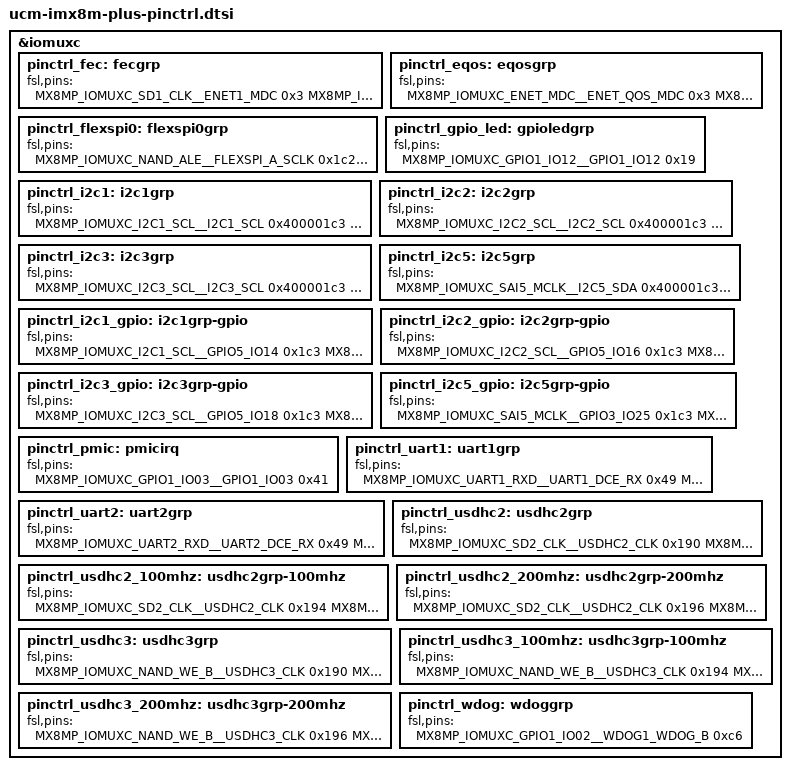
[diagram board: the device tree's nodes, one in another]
// SPDX-License-Identifier: (GPL-2.0+ OR MIT)
/*
 * Copyright 2022 CompuLab
 */

&iomuxc {
	pinctrl_fec: fecgrp {
		fsl,pins = <
			MX8MP_IOMUXC_SD1_CLK__ENET1_MDC					0x3
			MX8MP_IOMUXC_SD1_CMD__ENET1_MDIO				0x3
			MX8MP_IOMUXC_SD1_DATA2__ENET1_RGMII_RD0				0x91
			MX8MP_IOMUXC_SD1_DATA3__ENET1_RGMII_RD1				0x91
			MX8MP_IOMUXC_SAI1_RXD6__ENET1_RGMII_RD2				0x91
			MX8MP_IOMUXC_SAI1_RXD7__ENET1_RGMII_RD3				0x91
			MX8MP_IOMUXC_SAI1_TXC__ENET1_RGMII_RXC				0x91
			MX8MP_IOMUXC_SAI1_TXFS__ENET1_RGMII_RX_CTL			0x91
			MX8MP_IOMUXC_SD1_DATA1__ENET1_RGMII_TD0				0x1f
			MX8MP_IOMUXC_SD1_DATA0__ENET1_RGMII_TD1				0x1f
			MX8MP_IOMUXC_SAI1_TXD2__ENET1_RGMII_TD2				0x1f
			MX8MP_IOMUXC_SAI1_TXD3__ENET1_RGMII_TD3				0x1f
			MX8MP_IOMUXC_SAI1_TXD4__ENET1_RGMII_TX_CTL			0x1f
			MX8MP_IOMUXC_SAI1_TXD5__ENET1_RGMII_TXC				0x1f
		>;
	};
    
	pinctrl_eqos: eqosgrp {
		fsl,pins = <
			MX8MP_IOMUXC_ENET_MDC__ENET_QOS_MDC				0x3
			MX8MP_IOMUXC_ENET_MDIO__ENET_QOS_MDIO				0x3
			MX8MP_IOMUXC_ENET_RD0__ENET_QOS_RGMII_RD0			0x91
			MX8MP_IOMUXC_ENET_RD1__ENET_QOS_RGMII_RD1			0x91
			MX8MP_IOMUXC_ENET_RD2__ENET_QOS_RGMII_RD2			0x91
			MX8MP_IOMUXC_ENET_RD3__ENET_QOS_RGMII_RD3			0x91
			MX8MP_IOMUXC_ENET_RXC__CCM_ENET_QOS_CLOCK_GENERATE_RX_CLK	0x91
			MX8MP_IOMUXC_ENET_RX_CTL__ENET_QOS_RGMII_RX_CTL			0x91
			MX8MP_IOMUXC_ENET_TD0__ENET_QOS_RGMII_TD0			0x1f
			MX8MP_IOMUXC_ENET_TD1__ENET_QOS_RGMII_TD1			0x1f
			MX8MP_IOMUXC_ENET_TD2__ENET_QOS_RGMII_TD2			0x1f
			MX8MP_IOMUXC_ENET_TD3__ENET_QOS_RGMII_TD3			0x1f
			MX8MP_IOMUXC_ENET_TX_CTL__ENET_QOS_RGMII_TX_CTL			0x1f
			MX8MP_IOMUXC_ENET_TXC__CCM_ENET_QOS_CLOCK_GENERATE_TX_CLK	0x1f
			MX8MP_IOMUXC_GPIO1_IO10__GPIO1_IO10				0x19
		>;
	};

	pinctrl_flexspi0: flexspi0grp {
		fsl,pins = <
			MX8MP_IOMUXC_NAND_ALE__FLEXSPI_A_SCLK				0x1c2
			MX8MP_IOMUXC_NAND_CE0_B__FLEXSPI_A_SS0_B			0x82
			MX8MP_IOMUXC_NAND_DATA00__FLEXSPI_A_DATA00			0x82
			MX8MP_IOMUXC_NAND_DATA01__FLEXSPI_A_DATA01			0x82
			MX8MP_IOMUXC_NAND_DATA02__FLEXSPI_A_DATA02			0x82
			MX8MP_IOMUXC_NAND_DATA03__FLEXSPI_A_DATA03			0x82
		>;
	};

	pinctrl_gpio_led: gpioledgrp {
		fsl,pins = <
			MX8MP_IOMUXC_GPIO1_IO12__GPIO1_IO12				0x19
		>;
	};

	pinctrl_i2c1: i2c1grp {
		fsl,pins = <
			MX8MP_IOMUXC_I2C1_SCL__I2C1_SCL					0x400001c3
			MX8MP_IOMUXC_I2C1_SDA__I2C1_SDA					0x400001c3
		>;
	};

	pinctrl_i2c2: i2c2grp {
		fsl,pins = <
			MX8MP_IOMUXC_I2C2_SCL__I2C2_SCL					0x400001c3
			MX8MP_IOMUXC_I2C2_SDA__I2C2_SDA					0x400001c3
		>;
	};

	pinctrl_i2c3: i2c3grp {
		fsl,pins = <
			MX8MP_IOMUXC_I2C3_SCL__I2C3_SCL					0x400001c3
			MX8MP_IOMUXC_I2C3_SDA__I2C3_SDA					0x400001c3
		>;
	};

	pinctrl_i2c5: i2c5grp {
		fsl,pins = <
			MX8MP_IOMUXC_SAI5_MCLK__I2C5_SDA				0x400001c3
			MX8MP_IOMUXC_SAI5_RXD0__I2C5_SCL				0x400001c3
		>;
	};

	pinctrl_i2c1_gpio: i2c1grp-gpio {
		fsl,pins = <
			MX8MP_IOMUXC_I2C1_SCL__GPIO5_IO14				0x1c3
			MX8MP_IOMUXC_I2C1_SDA__GPIO5_IO15				0x1c3
		>;
	};

	pinctrl_i2c2_gpio: i2c2grp-gpio {
		fsl,pins = <
			MX8MP_IOMUXC_I2C2_SCL__GPIO5_IO16				0x1c3
			MX8MP_IOMUXC_I2C2_SDA__GPIO5_IO17				0x1c3
		>;
	};

	pinctrl_i2c3_gpio: i2c3grp-gpio {
		fsl,pins = <
			MX8MP_IOMUXC_I2C3_SCL__GPIO5_IO18				0x1c3
			MX8MP_IOMUXC_I2C3_SDA__GPIO5_IO19				0x1c3
		>;
	};

	pinctrl_i2c5_gpio: i2c5grp-gpio {
		fsl,pins = <
			MX8MP_IOMUXC_SAI5_MCLK__GPIO3_IO25				0x1c3
			MX8MP_IOMUXC_SAI5_RXD0__GPIO3_IO21				0x1c3
		>;
	};

	pinctrl_pmic: pmicirq {
		fsl,pins = <
			MX8MP_IOMUXC_GPIO1_IO03__GPIO1_IO03				0x41
		>;
	};

	pinctrl_uart1: uart1grp {
		fsl,pins = <
			MX8MP_IOMUXC_UART1_RXD__UART1_DCE_RX				0x49
			MX8MP_IOMUXC_UART1_TXD__UART1_DCE_TX				0x49
		>;
	};

	pinctrl_uart2: uart2grp {
		fsl,pins = <
			MX8MP_IOMUXC_UART2_RXD__UART2_DCE_RX				0x49
			MX8MP_IOMUXC_UART2_TXD__UART2_DCE_TX				0x49
		>;
	};

	pinctrl_usdhc2: usdhc2grp {
		fsl,pins = <
			MX8MP_IOMUXC_SD2_CLK__USDHC2_CLK				0x190
			MX8MP_IOMUXC_SD2_CMD__USDHC2_CMD				0x1d0
			MX8MP_IOMUXC_SD2_DATA0__USDHC2_DATA0				0x1d0
			MX8MP_IOMUXC_SD2_DATA1__USDHC2_DATA1				0x1d0
			MX8MP_IOMUXC_SD2_DATA2__USDHC2_DATA2				0x1d0
			MX8MP_IOMUXC_SD2_DATA3__USDHC2_DATA3				0x1d0
		>;
	};

	pinctrl_usdhc2_100mhz: usdhc2grp-100mhz {
		fsl,pins = <
			MX8MP_IOMUXC_SD2_CLK__USDHC2_CLK				0x194
			MX8MP_IOMUXC_SD2_CMD__USDHC2_CMD				0x1d4
			MX8MP_IOMUXC_SD2_DATA0__USDHC2_DATA0				0x1d4
			MX8MP_IOMUXC_SD2_DATA1__USDHC2_DATA1				0x1d4
			MX8MP_IOMUXC_SD2_DATA2__USDHC2_DATA2				0x1d4
			MX8MP_IOMUXC_SD2_DATA3__USDHC2_DATA3				0x1d4
		>;
	};

	pinctrl_usdhc2_200mhz: usdhc2grp-200mhz {
		fsl,pins = <
			MX8MP_IOMUXC_SD2_CLK__USDHC2_CLK				0x196
			MX8MP_IOMUXC_SD2_CMD__USDHC2_CMD				0x1d6
			MX8MP_IOMUXC_SD2_DATA0__USDHC2_DATA0				0x1d6
			MX8MP_IOMUXC_SD2_DATA1__USDHC2_DATA1				0x1d6
			MX8MP_IOMUXC_SD2_DATA2__USDHC2_DATA2				0x1d6
			MX8MP_IOMUXC_SD2_DATA3__USDHC2_DATA3				0x1d6
		>;
	};

	pinctrl_usdhc3: usdhc3grp {
		fsl,pins = <
			MX8MP_IOMUXC_NAND_WE_B__USDHC3_CLK				0x190
			MX8MP_IOMUXC_NAND_WP_B__USDHC3_CMD				0x1d0
			MX8MP_IOMUXC_NAND_DATA04__USDHC3_DATA0				0x1d0
			MX8MP_IOMUXC_NAND_DATA05__USDHC3_DATA1				0x1d0
			MX8MP_IOMUXC_NAND_DATA06__USDHC3_DATA2				0x1d0
			MX8MP_IOMUXC_NAND_DATA07__USDHC3_DATA3				0x1d0
			MX8MP_IOMUXC_NAND_RE_B__USDHC3_DATA4				0x1d0
			MX8MP_IOMUXC_NAND_CE2_B__USDHC3_DATA5				0x1d0
			MX8MP_IOMUXC_NAND_CE3_B__USDHC3_DATA6				0x1d0
			MX8MP_IOMUXC_NAND_CLE__USDHC3_DATA7				0x1d0
			MX8MP_IOMUXC_NAND_CE1_B__USDHC3_STROBE				0x190
		>;
	};

	pinctrl_usdhc3_100mhz: usdhc3grp-100mhz {
		fsl,pins = <
			MX8MP_IOMUXC_NAND_WE_B__USDHC3_CLK				0x194
			MX8MP_IOMUXC_NAND_WP_B__USDHC3_CMD				0x1d4
			MX8MP_IOMUXC_NAND_DATA04__USDHC3_DATA0				0x1d4
			MX8MP_IOMUXC_NAND_DATA05__USDHC3_DATA1				0x1d4
			MX8MP_IOMUXC_NAND_DATA06__USDHC3_DATA2				0x1d4
			MX8MP_IOMUXC_NAND_DATA07__USDHC3_DATA3				0x1d4
			MX8MP_IOMUXC_NAND_RE_B__USDHC3_DATA4				0x1d4
			MX8MP_IOMUXC_NAND_CE2_B__USDHC3_DATA5				0x1d4
			MX8MP_IOMUXC_NAND_CE3_B__USDHC3_DATA6				0x1d4
			MX8MP_IOMUXC_NAND_CLE__USDHC3_DATA7				0x1d4
			MX8MP_IOMUXC_NAND_CE1_B__USDHC3_STROBE				0x194
		>;
	};

	pinctrl_usdhc3_200mhz: usdhc3grp-200mhz {
		fsl,pins = <
			MX8MP_IOMUXC_NAND_WE_B__USDHC3_CLK				0x196
			MX8MP_IOMUXC_NAND_WP_B__USDHC3_CMD				0x1d6
			MX8MP_IOMUXC_NAND_DATA04__USDHC3_DATA0				0x1d6
			MX8MP_IOMUXC_NAND_DATA05__USDHC3_DATA1				0x1d6
			MX8MP_IOMUXC_NAND_DATA06__USDHC3_DATA2				0x1d6
			MX8MP_IOMUXC_NAND_DATA07__USDHC3_DATA3				0x1d6
			MX8MP_IOMUXC_NAND_RE_B__USDHC3_DATA4				0x1d6
			MX8MP_IOMUXC_NAND_CE2_B__USDHC3_DATA5				0x1d6
			MX8MP_IOMUXC_NAND_CE3_B__USDHC3_DATA6				0x1d6
			MX8MP_IOMUXC_NAND_CLE__USDHC3_DATA7				0x1d6
			MX8MP_IOMUXC_NAND_CE1_B__USDHC3_STROBE				0x196
		>;
	};

	pinctrl_wdog: wdoggrp {
		fsl,pins = <
			MX8MP_IOMUXC_GPIO1_IO02__WDOG1_WDOG_B				0xc6
		>;
	};
};
